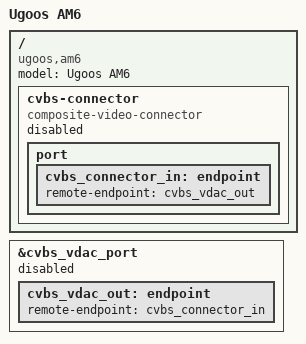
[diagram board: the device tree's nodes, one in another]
// SPDX-License-Identifier: (GPL-2.0+ OR MIT)
/*
 * Copyright (c) 2019 BayLibre, SAS
 * Author: Neil Armstrong <narmstrong@baylibre.com>
 * Copyright (c) 2019 Christian Hewitt <christianshewitt@gmail.com>
 */

/dts-v1/;

#include "meson-g12b-ugoos-am6.dts"

/ {
	compatible = "ugoos,am6", "amlogic,g12b";
	model = "Ugoos AM6";

	cvbs-connector {
		status = "disable";
		compatible = "composite-video-connector";

		port {
			cvbs_connector_in: endpoint {
				remote-endpoint = <&cvbs_vdac_out>;
			};
		};
	};

};

&cvbs_vdac_port {
	status = "disable";
	cvbs_vdac_out: endpoint {
		remote-endpoint = <&cvbs_connector_in>;
	};
};
